# AIC8800 register map
File version: 1.2
CPU: CM4 r0p1, little endian, no MPU, no FPU, 6 interrupt priority bits
Registers are 32-bit, read-write, reset 0x0 unless marked. A register's access mark holds for its fields unless they carry their own. Offsets are from the block's base; lines under a group give offsets from that group; [hi:lo] are bit positions; {n}, {i} and the like mark numbered series; 'fields as' and 'values as' point back to an identical list; <NAME> marks a mode.

## Memory map
0x40102000 I2CM0 size 0x30 — Inter-integrated circuit
0x40504000 GPIOA size 0x30 — General Purpose Input/Output
0xE000E010 STK size 0x11 — SysTick timer
0xE000ED00 SCB size 0x41 — System control block
0xE000ED90 MPU size 0x15 — Memory protection unit

## I2CM0 — Inter-integrated circuit
Base 0x40102000
0x00 CR — Cfg Register
0x04 SAR — Slave Addr Register
0x08 LR — Len Register
0x0C IR ro — In Register
0x10 OR wo — Out Register
0x14 SR ro — Stat Register
0x20 DR0 — Div Register
0x24 DR1 — Div Register
0x28 SCR — St Cnt Register
0x2C RR — Rst Register

## GPIOA — General Purpose Input/Output
Base 0x40504000
0x00 VR — Val Register
0x04 MR — Msk Register
0x08 DR — Dir Register
0x0C TELR — Trig Edg or Lvl Reg
0x10 TER — Trig Edg Reg
0x14 TLR — Trig Lvl Reg
0x18 ICR — Int Ctrl Reg
0x20 ISR ro — Int Stat Reg
0x24 IRR wo — Int Rm Reg
0x28 TIR — Trig In Reg
0x2C FR — Fltr Reg

## MPU — Memory protection unit
Base 0xE000ED90
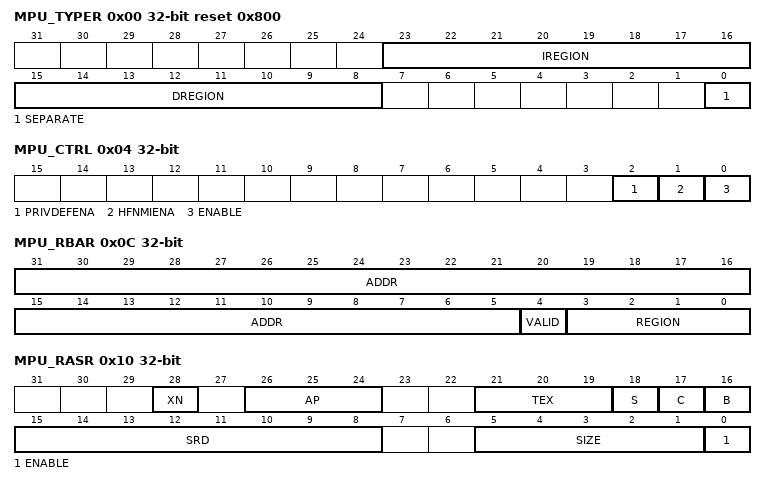
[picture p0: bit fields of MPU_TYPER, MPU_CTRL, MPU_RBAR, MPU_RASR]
0x00 MPU_TYPER ro reset 0x800 — MPU type register
  [23:16] IREGION — Number of MPU instruction regions
  [15:8] DREGION — Number of MPU data regions
  [0] SEPARATE — Separate flag
0x04 MPU_CTRL ro — MPU control register
  [2] PRIVDEFENA — Enable priviliged software access to default memory map
  [1] HFNMIENA — Enables the operation of MPU during hard fault
  [0] ENABLE — Enables the MPU
0x08 MPU_RNR — MPU region number register
  [7:0] REGION — MPU region
0x0C MPU_RBAR — MPU region base address register
  [31:5] ADDR — Region base address field
  [4] VALID — MPU region number valid
  [3:0] REGION — MPU region field
0x10 MPU_RASR — MPU region attribute and size register
  [28] XN — Instruction access disable bit
  [26:24] AP — Access permission
  [21:19] TEX — memory attribute
  [18] S — Shareable memory attribute
  [17] C — memory attribute
  [16] B — memory attribute
  [15:8] SRD — Subregion disable bits
  [5:1] SIZE — Size of the MPU protection region
  [0] ENABLE — Region enable bit.

## STK — SysTick timer
Base 0xE000E010
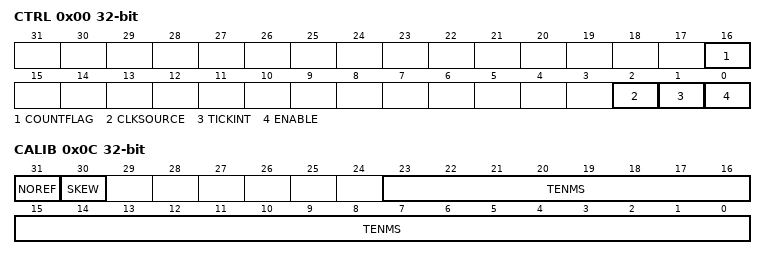
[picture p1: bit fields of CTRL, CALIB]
0x00 CTRL — SysTick control and status register
  [16] COUNTFLAG
  [2] CLKSOURCE — Clock source selection
  [1] TICKINT — SysTick exception request enable
  [0] ENABLE — Counter enable
0x04 LOAD — SysTick reload value register
  [23:0] RELOAD — RELOAD value
0x08 VAL — SysTick current value register
  [23:0] CURRENT — Current counter value
0x0C CALIB — SysTick calibration value register
  [31] NOREF — NOREF flag. Reads as zero
  [30] SKEW — SKEW flag: Indicates whether the TENMS value is exact
  [23:0] TENMS — Calibration value
